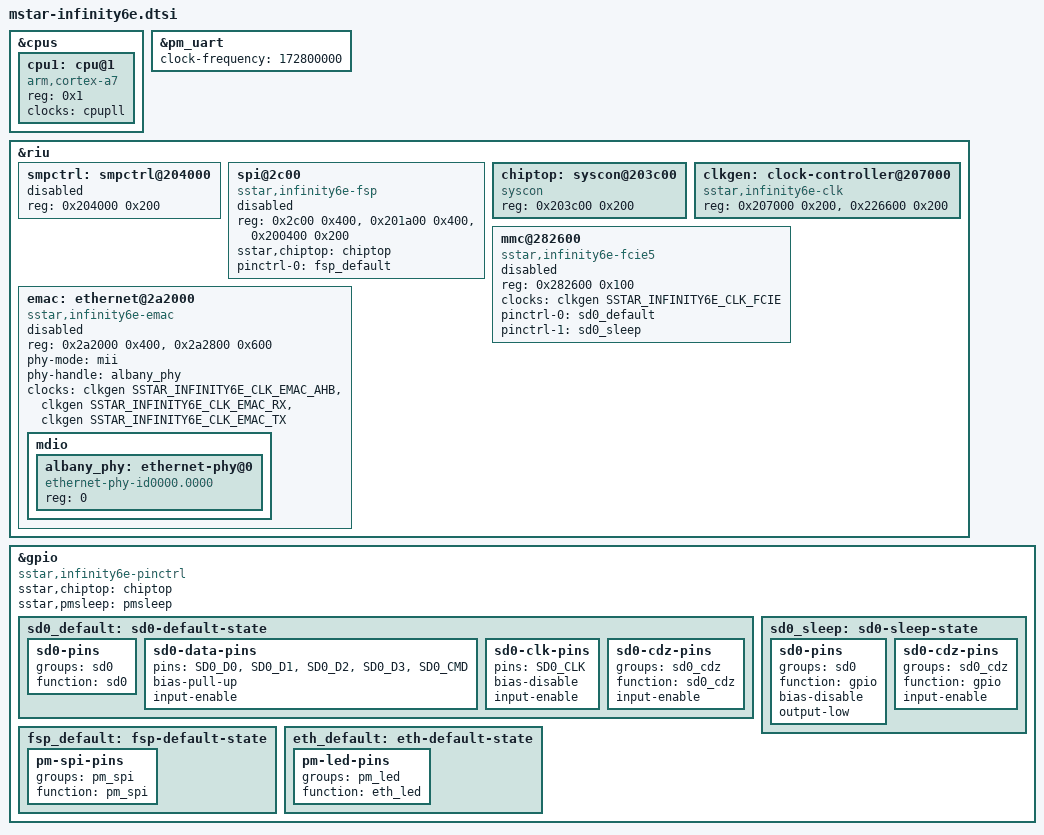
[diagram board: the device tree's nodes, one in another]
// SPDX-License-Identifier: GPL-2.0-or-later
/*
 * Copyright (c) 2026 Petr Kracik <petrkr@petrkr.net>
 */

#include "mstar-v7.dtsi"

#include <dt-bindings/clock/sstar-infinity6e.h>

&cpus {
	cpu1: cpu@1 {
		device_type = "cpu";
		compatible = "arm,cortex-a7";
		reg = <0x1>;
		clocks = <&cpupll>;
		clock-names = "cpuclk";
	};
};

&pm_uart {
	clock-frequency = <172800000>;
};

&riu {
	smpctrl: smpctrl@204000 {
		reg = <0x204000 0x200>;
		status = "disabled";
	};

	spi@2c00 {
		compatible = "sstar,infinity6e-fsp";
		reg = <0x2c00 0x400>, <0x201a00 0x400>, <0x200400 0x200>;
		reg-names = "fsp-pm", "fsp-nonpm", "bdma";
		sstar,chiptop = <&chiptop>;
		pinctrl-names = "default";
		pinctrl-0 = <&fsp_default>;
		#address-cells = <1>;
		#size-cells = <0>;
		status = "disabled";
	};

	chiptop: syscon@203c00 {
		compatible = "syscon";
		reg = <0x203c00 0x200>;
	};

	clkgen: clock-controller@207000 {
		compatible = "sstar,infinity6e-clk";
		reg = <0x207000 0x200>, <0x226600 0x200>;
		#clock-cells = <1>;
	};

	mmc@282600 {
		compatible = "sstar,infinity6e-fcie5";
		reg = <0x282600 0x100>;
		clocks = <&clkgen SSTAR_INFINITY6E_CLK_FCIE>;
		clock-names = "fcie";
		pinctrl-names = "default", "sleep";
		pinctrl-0 = <&sd0_default>;
		pinctrl-1 = <&sd0_sleep>;
		status = "disabled";
	};

	emac: ethernet@2a2000 {
		compatible = "sstar,infinity6e-emac";
		reg = <0x2a2000 0x400>, <0x2a2800 0x600>;
		reg-names = "emac", "phy";
		phy-mode = "mii";
		phy-handle = <&albany_phy>;
		clocks = <&clkgen SSTAR_INFINITY6E_CLK_EMAC_AHB>,
			 <&clkgen SSTAR_INFINITY6E_CLK_EMAC_RX>,
			 <&clkgen SSTAR_INFINITY6E_CLK_EMAC_TX>;
		clock-names = "ahb", "rx", "tx";
		status = "disabled";

		mdio {
			#address-cells = <1>;
			#size-cells = <0>;

			albany_phy: ethernet-phy@0 {
				compatible = "ethernet-phy-id0000.0000";
				reg = <0>;
			};
		};
	};
};

&gpio {
	compatible = "sstar,infinity6e-pinctrl";
	sstar,chiptop = <&chiptop>;
	sstar,pmsleep = <&pmsleep>;

	sd0_default: sd0-default-state {
		sd0-pins {
			groups = "sd0";
			function = "sd0";
		};

		sd0-data-pins {
			pins = "SD0_D0", "SD0_D1", "SD0_D2", "SD0_D3", "SD0_CMD";
			bias-pull-up;
			input-enable;
		};

		sd0-clk-pins {
			pins = "SD0_CLK";
			bias-disable;
			input-enable;
		};

		sd0-cdz-pins {
			groups = "sd0_cdz";
			function = "sd0_cdz";
			input-enable;
		};
	};

	sd0_sleep: sd0-sleep-state {
		sd0-pins {
			groups = "sd0";
			function = "gpio";
			bias-disable;
			output-low;
		};

		sd0-cdz-pins {
			groups = "sd0_cdz";
			function = "gpio";
			input-enable;
		};
	};

	fsp_default: fsp-default-state {
		pm-spi-pins {
			groups = "pm_spi";
			function = "pm_spi";
		};
	};

	eth_default: eth-default-state {
		pm-led-pins {
			groups = "pm_led";
			function = "eth_led";
		};
	};
};
